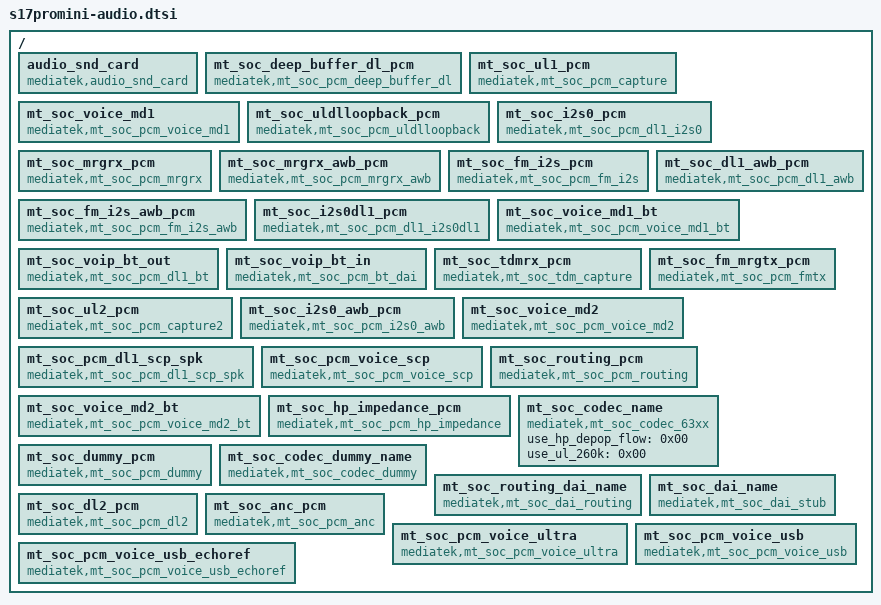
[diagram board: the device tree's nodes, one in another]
// SPDX-License-Identifier: GPL-2.0-only
/* S17 Pro mini audio configuration; included by s17promini.dtsi. */

/ {
	audio_snd_card {
		compatible = "mediatek,audio_snd_card";
	};

	mt_soc_deep_buffer_dl_pcm {
		compatible = "mediatek,mt_soc_pcm_deep_buffer_dl";
	};

	mt_soc_ul1_pcm {
		compatible = "mediatek,mt_soc_pcm_capture";
	};

	mt_soc_voice_md1 {
		compatible = "mediatek,mt_soc_pcm_voice_md1";
	};

	mt_soc_uldlloopback_pcm {
		compatible = "mediatek,mt_soc_pcm_uldlloopback";
	};

	mt_soc_i2s0_pcm {
		compatible = "mediatek,mt_soc_pcm_dl1_i2s0";
	};

	mt_soc_mrgrx_pcm {
		compatible = "mediatek,mt_soc_pcm_mrgrx";
	};

	mt_soc_mrgrx_awb_pcm {
		compatible = "mediatek,mt_soc_pcm_mrgrx_awb";
	};

	mt_soc_fm_i2s_pcm {
		compatible = "mediatek,mt_soc_pcm_fm_i2s";
	};

	mt_soc_fm_i2s_awb_pcm {
		compatible = "mediatek,mt_soc_pcm_fm_i2s_awb";
	};

	mt_soc_i2s0dl1_pcm {
		compatible = "mediatek,mt_soc_pcm_dl1_i2s0dl1";
	};

	mt_soc_dl1_awb_pcm {
		compatible = "mediatek,mt_soc_pcm_dl1_awb";
	};

	mt_soc_voice_md1_bt {
		compatible = "mediatek,mt_soc_pcm_voice_md1_bt";
	};

	mt_soc_voip_bt_out {
		compatible = "mediatek,mt_soc_pcm_dl1_bt";
	};

	mt_soc_voip_bt_in {
		compatible = "mediatek,mt_soc_pcm_bt_dai";
	};

	mt_soc_tdmrx_pcm {
		compatible = "mediatek,mt_soc_tdm_capture";
	};

	mt_soc_fm_mrgtx_pcm {
		compatible = "mediatek,mt_soc_pcm_fmtx";
	};

	mt_soc_ul2_pcm {
		compatible = "mediatek,mt_soc_pcm_capture2";
	};

	mt_soc_i2s0_awb_pcm {
		compatible = "mediatek,mt_soc_pcm_i2s0_awb";
	};

	mt_soc_voice_md2 {
		compatible = "mediatek,mt_soc_pcm_voice_md2";
	};

	mt_soc_pcm_dl1_scp_spk {
		compatible = "mediatek,mt_soc_pcm_dl1_scp_spk";
	};

	mt_soc_pcm_voice_scp {
		compatible = "mediatek,mt_soc_pcm_voice_scp";
	};

	mt_soc_routing_pcm {
		compatible = "mediatek,mt_soc_pcm_routing";
	};

	mt_soc_voice_md2_bt {
		compatible = "mediatek,mt_soc_pcm_voice_md2_bt";
	};

	mt_soc_hp_impedance_pcm {
		compatible = "mediatek,mt_soc_pcm_hp_impedance";
	};

	mt_soc_codec_name {
		compatible = "mediatek,mt_soc_codec_63xx";
		use_hp_depop_flow = <0x00>;
		use_ul_260k = <0x00>;
	};

	mt_soc_dummy_pcm {
		compatible = "mediatek,mt_soc_pcm_dummy";
	};

	mt_soc_codec_dummy_name {
		compatible = "mediatek,mt_soc_codec_dummy";
	};

	mt_soc_routing_dai_name {
		compatible = "mediatek,mt_soc_dai_routing";
	};

	mt_soc_dai_name {
		compatible = "mediatek,mt_soc_dai_stub";
	};

	mt_soc_dl2_pcm {
		compatible = "mediatek,mt_soc_pcm_dl2";
	};

	mt_soc_anc_pcm {
		compatible = "mediatek,mt_soc_pcm_anc";
	};

	mt_soc_pcm_voice_ultra {
		compatible = "mediatek,mt_soc_pcm_voice_ultra";
	};

	mt_soc_pcm_voice_usb {
		compatible = "mediatek,mt_soc_pcm_voice_usb";
	};

	mt_soc_pcm_voice_usb_echoref {
		compatible = "mediatek,mt_soc_pcm_voice_usb_echoref";
	};
};
